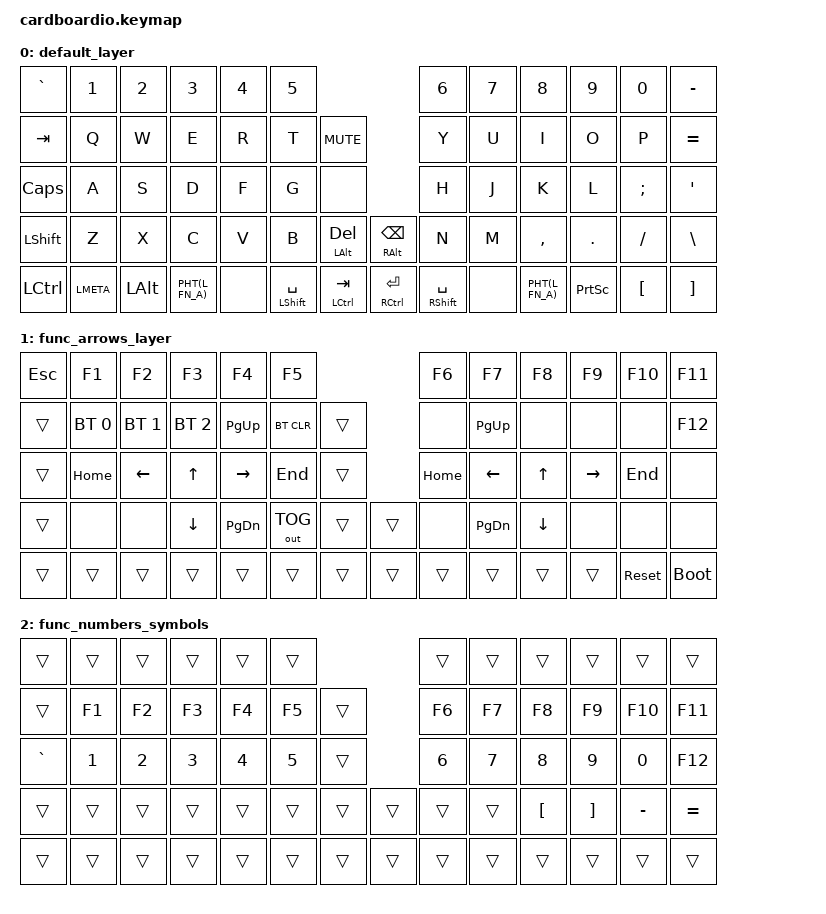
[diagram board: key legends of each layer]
/*
 * Copyright (c) 2020 The ZMK Contributors
 *
 * SPDX-License-Identifier: MIT
 */

#include <behaviors.dtsi>
#include <dt-bindings/zmk/keys.h>
#include <dt-bindings/zmk/bt.h>
#include <dt-bindings/zmk/outputs.h>

#define LAYER_DEFAULT 0
#define L_FN_A 1
#define L_NUM_SYM 2
#define PHT(layer) &pht layer layer

/ {
        combos {
                compatible = "zmk,combos";
                combo_esc {
                        key-positions = <0 12>;
                        bindings = <&kp ESC>;
                };
                combo_lbkt {
                        key-positions = <34 48>;
                        bindings = <&kp LBKT>;
                };
                combo_lbrace {
                        key-positions = <21 34>;
                        bindings = <&kp LBRC>;
                };
                combo_rbkt {
                        key-positions = <35 49>;
                        bindings = <&kp RBKT>;
                };
                combo_rbrace {
                        key-positions = <22 35>;
                        bindings = <&kp RBRC>;
                };
                combo_f1 {
                        key-positions = <1 13>;
                        bindings = <&kp F1>;
                };
                combo_f2 {
                        key-positions = <2 14>;
                        bindings = <&kp F2>;
                };
                combo_f3 {
                        key-positions = <3 15>;
                        bindings = <&kp F3>;
                };
                combo_f4 {
                        key-positions = <4 16>;
                        bindings = <&kp F3>;
                };
                combo_f5 {
                        key-positions = <5 17>;
                        bindings = <&kp F5>;
                };
                combo_f6 {
                        key-positions = <6 18>;
                        bindings = <&kp F6>;
                };
                combo_f7 {
                        key-positions = <7 19>;
                        bindings = <&kp F7>;
                };
                combo_f8 {
                        key-positions = <8 20>;
                        bindings = <&kp F8>;
                };
                combo_f9 {
                        key-positions = <9 21>;
                        bindings = <&kp F9>;
                };
                combo_f10 {
                        key-positions = <10 22>;
                        bindings = <&kp F10>;
                };
                combo_f11 {
                        key-positions = <11 23>;
                        bindings = <&kp F11>;
                };
                combo_f12 {
                        key-positions = <23 37>;
                        bindings = <&kp F11>;
                };
                combo_meta {
                        key-positions = <26 39>;
                        bindings = <&kp LMETA>;
                };
                combo_prt_scn {
                        key-positions = <36 50>;
                        bindings = <&kp PSCRN>;
                };
        };

        behaviors {
                pht: palm_hold_tap {
                        compatible = "zmk,behavior-hold-tap";
                        label = "PALM_HOLD_TAP";
                        #binding-cells = <2>;
                        flavor = "hold-preferred";
                        tapping-term-ms = <200>;
                        bindings = <&mo &tog>;
                };

                /* phtd: palm_hold_tap_dance {
                        compatible = "zmk,behavior-tap-dance";
                        label = "PALM_HOLD_TAP_DANCE";
                        #binding-cells = <0>;
                        tapping-term-ms = <200>;
                        bindings = <&pht L_FN_A L_FN_A>, <&pht L_NUM_SYM L_NUM_SYM>;
                }; */

                mmt: my_mod_tap {
                        compatible = "zmk,behavior-hold-tap";
                        label = "MY_MOD_TAP";
                        #binding-cells = <2>;
                        flavor = "balanced";
                        tapping-term-ms = <150>;
                        bindings = <&kp &kp>;
                };
        };

        keymap {
                compatible = "zmk,keymap";

                default_layer {
/* QWERTY
 *    +------+------+------+------+------+------+                             +------+------+------+------+------+------+
 * 0  |  `   |  1   |  2   |  3   |  4   |  5   |       ------             6  |  6   |  7   |  8   |  9   |  0   |  -   |
 *    +------+------+------+------+------+------+      ( Mute )               +------+------+------+------+------+------+
 * 12 |  ⇥   |  Q   |  W   |  E   |  R   |  T   |       ------             19 |  Y   |  U   |  I   |  O   |  P   |  =   |
 *    +------+------+------+------+------+------+   ------                    +------+------+------+------+------+------+
 * 25 | Caps |  A   |  S   |  D   |  F   |  G   |  (      )                32 |  H   |  J   |  K   |  L   |  ;   |  '   |
 *    +------+------+------+------+------+------+   ------                    +------+------+------+------+------+------+
 * 38 | Shift|  Z   |  X   |  C   |  V   |  B   |    +------+     +------+    |  N   |  M   |  ,   |  .   |  /   |  \   |
 *    +------+------+------+------+------+------+    | ⌦/Alt|  45 | ⌫/Alt|    +------+------+------+------+------+------+
 * 52 | Ctrl | Win  | Alt  |           +------+------+------+     +------+------+------+           | PtSc |  [   |  ]   |
 *    +------+------+------+           |  L↓  | ␣/⇧  | ⇥/Ctl|  59 | ⏎/Ctl| ␣/⇧  |  L↑  |           +------+------+------+
 *                                     +------+------+------+     +------+------+------+
 *                         +------+                                                         +------+
 *                      55 | Layr |                                                      62 | Layr |
 *                         +------+                                                         +------+
 */
                        bindings = <
&kp GRAVE       &kp N1          &kp N2          &kp N3          &kp N4          &kp N5                                          &kp N6          &kp N7          &kp N8          &kp N9          &kp N0          &kp MINUS
&kp TAB         &kp Q           &kp W           &kp E           &kp R           &kp T           &kp C_MUTE                      &kp Y           &kp U           &kp I           &kp O           &kp P           &kp EQUAL
&kp CAPS        &kp A           &kp S           &kp D           &kp F           &kp G           &none                           &kp H           &kp J           &kp K           &kp L           &kp SEMI        &kp APOS
&kp LSHFT       &kp Z           &kp X           &kp C           &kp V           &kp B           &mmt LALT DEL   &mmt RALT BSPC  &kp N           &kp M           &kp COMMA       &kp PERIOD      &kp FSLH        &kp BSLH
&kp LCTRL       &kp LMETA       &kp LALT        PHT(L_FN_A)     &none           &mmt LSHFT SPACE &mmt LCTRL TAB &mmt RCTRL RET  &mmt RSHFT SPACE &none          PHT(L_FN_A)     &kp PSCRN       &kp LBKT        &kp RBKT
                        >;

                        sensor-bindings = <
                                &inc_dec_kp C_VOL_UP C_VOL_DN
                                &inc_dec_kp K_REDO K_UNDO
                                &inc_dec_kp UP DOWN
                                &inc_dec_kp LEFT RIGHT
                        >;
                };

                func_arrows_layer {
/* Esc, function row, and alternate arrow keys
 * +------+------+------+------+------+------+                            +------+------+------+------+------+------+
 * |  Esc |  F1  |  F2  |  F3  |  F4  |  F5  |       ------               |  F6  |  F7  |  F8  |  F9  |  F10 |  F11 |
 * +------+------+------+------+------+------+      (      )              +------+------+------+------+------+------+
 * |      | BT0  | BT1  | BT2  | PgUp | BTC  |       ------               |      | PgUp |      |      |      |  F12 |
 * +------+------+------+------+------+------+   ------                   +------+------+------+------+------+------+
 * |      | Home |  ←   |  ↑   |  →   | End  |  (      )                  | Home |  ←   |  ↑   |  →   |  End |      |
 * +------+------+------+------+------+------+   ------                   +------+------+------+------+------+------+
 * |      |      |      |  ↓   | PgDn | TOG  |    +------+    +------+    |      | PgDn |  ↓   |      |      |      |
 * +------+------+------+------+------+------+    |      |    |      |    +------+------+------+------+------+------+
 * |      |      |      |           +------+------+------+    +------+------+------+           |      | Rst  | Boot |
 * +------+------+------+           |      |      |      |    |      |      |      |           +------+------+------+
 *                                  +------+------+------+    +------+------+------+
 *                      +------+                                                        +------+
 *                      |      |                                                        |      |
 *                      +------+                                                        +------+
 */
                        bindings = <
&kp ESC         &kp F1          &kp F2          &kp F3          &kp F4          &kp F5                                          &kp F6          &kp F7          &kp F8          &kp F9          &kp F10         &kp F11
&trans          &bt BT_SEL 0    &bt BT_SEL 1    &bt BT_SEL 2    &kp PG_UP       &bt BT_CLR      &trans                          &none           &kp PG_UP       &none           &none           &none           &kp F12
&trans          &kp HOME        &kp LEFT        &kp UP          &kp RIGHT       &kp END         &trans                          &kp HOME        &kp LEFT        &kp UP          &kp RIGHT       &kp END         &none
&trans          &none           &none           &kp DOWN        &kp PG_DN       &out OUT_TOG    &trans          &trans          &none           &kp PG_DN       &kp DOWN        &none           &none           &none
&trans          &trans          &trans          &trans          &trans          &trans          &trans          &trans          &trans          &trans          &trans          &trans          &sys_reset      &bootloader                        >;

                        sensor-bindings = <
                                /* Trans isn't supported for sensors; just redo the first two bindings */
                                &inc_dec_kp C_VOL_UP C_VOL_DN
                                &inc_dec_kp K_REDO K_UNDO
                                &inc_dec_kp PG_UP PG_DN
                                &inc_dec_kp BSPC DEL
                        >;
                };

                func_numbers_symbols {
/* Esc, function row, and alternate arrow keys
 * +------+------+------+------+------+------+                            +------+------+------+------+------+------+
 * |      |      |      |      |      |      |       ------               |      |      |      |      |      |      |
 * +------+------+------+------+------+------+      (      )              +------+------+------+------+------+------+
 * |      |  F1  |  F2  |  F3  |  F4  |  F5  |       ------               |  F6  |  F7  | F8   |  F9  | F10  | F11  |
 * +------+------+------+------+------+------+   ------                   +------+------+------+------+------+------+
 * |  `   |  1   |  2   |  3   |  4   |  5   |  (      )                  |  6   |  7   |  8   |  9   |  0   | F12  |
 * +------+------+------+------+------+------+   ------                   +------+------+------+------+------+------+
 * |      |      |      |      |      |      |    +------+    +------+    |      |      |  [   |  ]   |  -   |  =   |
 * +------+------+------+------+------+------+    |      |    |      |    +------+------+------+------+------+------+
 * |      |      |      |           +------+------+------+    +------+------+------+           |      |      |      |
 * +------+------+------+           |      |      |      |    |      |      |      |           +------+------+------+
 *                                  +------+------+------+    +------+------+------+
 *                      +------+                                                        +------+
 *                      |      |                                                        |      |
 *                      +------+                                                        +------+
 */
                        bindings = <
&trans          &trans          &trans          &trans          &trans          &trans                                          &trans          &trans          &trans          &trans          &trans          &trans
&trans          &kp F1          &kp F2          &kp F3          &kp F4          &kp F5          &trans                          &kp F6          &kp F7          &kp F8          &kp F9          &kp F10         &kp F11
&kp GRAVE       &kp N1          &kp N2          &kp N3          &kp N4          &kp N5          &trans                          &kp N6          &kp N7          &kp N8          &kp N9          &kp N0          &kp F12
&trans          &trans          &trans          &trans          &trans          &trans          &trans          &trans          &trans          &trans          &kp LBKT        &kp RBKT        &kp MINUS       &kp EQUAL
&trans          &trans          &trans          &trans          &trans          &trans          &trans          &trans          &trans          &trans          &trans          &trans          &trans          &trans                        >;
                };
        };
};

